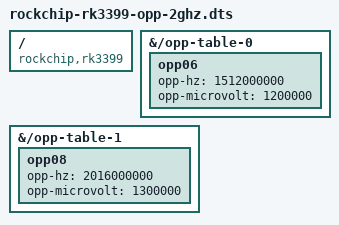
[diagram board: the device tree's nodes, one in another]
/dts-v1/;

/ {
    compatible = "rockchip,rk3399";
    fragment@0 {
        target-path = "/opp-table-0";
        __overlay__ {
		opp06 {
			opp-hz = /bits/ 64 <1512000000>;
			opp-microvolt = <1200000>;
		};
        };
    };

    fragment@1 {
        target-path = "/opp-table-1";
        __overlay__ {
		opp08 {
			opp-hz = /bits/ 64 <2016000000>;
			opp-microvolt = <1300000>;
		};
        };
    };
};
